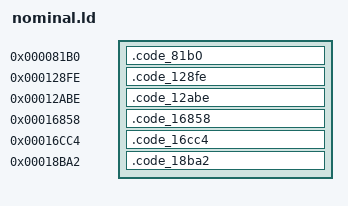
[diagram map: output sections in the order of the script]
OUTPUT_ARCH(riscv)
ENTRY(tsl9_queue_external_12abe)
PHDRS { code PT_LOAD FLAGS(5); }
SECTIONS {
  .code_81b0 0x81b0 : ALIGN(2) {
    KEEP(*(.text.tsl9_channel_external_81b0))
    KEEP(*(.text.tsl9_channel_clock_frame_81b6))
    KEEP(*(.text.tsl9_channel_clock_scale_81bc))
  } :code
  ASSERT(SIZEOF(.code_81b0) == 26, "Exact original extent")
  .code_128fe 0x128fe : ALIGN(2) {
    KEEP(*(.text.tsl9_channel_external_128fe))
    KEEP(*(.text.tsl9_filter_input_frame_12904))
    KEEP(*(.text.tsl9_filter_input_fill_1290a))
    KEEP(*(.text.tsl9_filter_input_cap_12920))
    KEEP(*(.text.tsl9_filter_input_small_1292c))
    KEEP(*(.text.tsl9_filter_input_copy_12930))
    KEEP(*(.text.tsl9_filter_input_loop_init_1293c))
    KEEP(*(.text.tsl9_filter_input_loop_12946))
    KEEP(*(.text.tsl9_filter_input_next_1298a))
    KEEP(*(.text.tsl9_filter_input_finish_1298e))
  } :code
  ASSERT(SIZEOF(.code_128fe) == 160, "Exact original extent")
  .code_12abe 0x12abe : ALIGN(2) {
    KEEP(*(.text.tsl9_queue_external_12abe))
    KEEP(*(.text.tsl9_channel_zero_12ac2))
    KEEP(*(.text.tsl9_channel_nonzero_12aca))
  } :code
  ASSERT(SIZEOF(.code_12abe) == 18, "Exact original extent")
  .code_16858 0x16858 : ALIGN(2) {
    KEEP(*(.text.tsl9_channel_external_16858))
    KEEP(*(.text.tsl9_channel_timer_args_1685a))
    KEEP(*(.text.tsl9_channel_timer_nonzero_16876))
    KEEP(*(.text.tsl9_channel_timer_zero_16888))
    KEEP(*(.text.tsl9_spi_transfer_entry_16896))
    KEEP(*(.text.tsl9_spi_tx_poll_1689e))
    KEEP(*(.text.tsl9_spi_tx_ready_168a6))
    KEEP(*(.text.tsl9_spi_rx_poll_168b6))
    KEEP(*(.text.tsl9_spi_rx_done_168be))
    KEEP(*(.text.tsl9_spi_tx_wait_168c8))
    KEEP(*(.text.tsl9_spi_timeout_168d0))
    KEEP(*(.text.tsl9_spi_rx_wait_168d4))
    KEEP(*(.text.tsl9_tagged_external_168de))
    KEEP(*(.text.tsl9_spi_write_guard1_168e6))
    KEEP(*(.text.tsl9_spi_write_select1_168f0))
    KEEP(*(.text.tsl9_spi_write_guard2_168fa))
    KEEP(*(.text.tsl9_spi_write_select2_168fe))
    KEEP(*(.text.tsl9_spi_write_command_16908))
    KEEP(*(.text.tsl9_spi_write_address_16910))
    KEEP(*(.text.tsl9_spi_write_test_1691a))
    KEEP(*(.text.tsl9_spi_write_finish_1691e))
    KEEP(*(.text.tsl9_spi_write_payload_16932))
    KEEP(*(.text.tsl9_tagged_external_1693e))
    KEEP(*(.text.tsl9_spi_modify_guard1_16942))
    KEEP(*(.text.tsl9_spi_modify_select1_16948))
    KEEP(*(.text.tsl9_spi_modify_guard2_16952))
    KEEP(*(.text.tsl9_spi_modify_select2_16956))
    KEEP(*(.text.tsl9_spi_modify_command_16960))
    KEEP(*(.text.tsl9_spi_modify_address_1696c))
    KEEP(*(.text.tsl9_spi_modify_mask_16974))
    KEEP(*(.text.tsl9_spi_modify_value_1697c))
    KEEP(*(.text.tsl9_spi_modify_finish_16984))
    KEEP(*(.text.tsl9_register_read_entry_16994))
    KEEP(*(.text.tsl9_register_read_body))
    KEEP(*(.text.tsl9_channel_external_169dc))
    KEEP(*(.text.tsl9_channel_mode_write_169e2))
    KEEP(*(.text.tsl9_channel_clock_start_169f8))
    KEEP(*(.text.tsl9_channel_poll_setup_169fc))
    KEEP(*(.text.tsl9_channel_poll_clock_16a00))
    KEEP(*(.text.tsl9_channel_timeout_16a0c))
    KEEP(*(.text.tsl9_channel_mode_return_16a0e))
    KEEP(*(.text.tsl9_channel_poll_read_16a1c))
    KEEP(*(.text.tsl9_channel_mode_done_16a2c))
    KEEP(*(.text.tsl9_register_write_entry_16a30))
    KEEP(*(.text.tsl9_register_write_body))
  } :code
  ASSERT(SIZEOF(.code_16858) == 548, "Exact original extent")
  .code_16cc4 0x16cc4 : ALIGN(2) {
    KEEP(*(.text.tsl9_channel_external_16cc4))
    KEEP(*(.text.tsl9_setup_resident_16cd2))
    KEEP(*(.text.tsl9_setup_frame_16cd8))
    KEEP(*(.text.tsl9_setup_clear_16ce6))
    KEEP(*(.text.tsl9_setup_length_16cfa))
    KEEP(*(.text.tsl9_setup_clamp_16d04))
    KEEP(*(.text.tsl9_setup_copy_16d06))
    KEEP(*(.text.tsl9_setup_mode_16d12))
    KEEP(*(.text.tsl9_setup_write0_16d1c))
    KEEP(*(.text.tsl9_setup_write1_16d2a))
    KEEP(*(.text.tsl9_setup_loop_init_16d3e))
    KEEP(*(.text.tsl9_setup_loop_16d4c))
    KEEP(*(.text.tsl9_setup_test_16d82))
    KEEP(*(.text.tsl9_setup_normal_16d86))
    KEEP(*(.text.tsl9_setup_final_16d8e))
    KEEP(*(.text.tsl9_setup_return_16d96))
    KEEP(*(.text.tsl9_setup_early_16daa))
  } :code
  ASSERT(SIZEOF(.code_16cc4) == 232, "Exact original extent")
  .code_18ba2 0x18ba2 : ALIGN(2) {
    KEEP(*(.text.tsl9_filter_program_18ba2))
    KEEP(*(.text.tsl9_filter_scale16_18bd4))
    KEEP(*(.text.tsl9_filter_fr2_18bfe))
    KEEP(*(.text.tsl9_filter_mode_18c04))
    KEEP(*(.text.tsl9_filter_mode_mask_18c12))
    KEEP(*(.text.tsl9_filter_mode_store_18c18))
    KEEP(*(.text.tsl9_filter_fifo_18c1c))
    KEEP(*(.text.tsl9_filter_fifo0_18c2a))
    KEEP(*(.text.tsl9_filter_activation_18c34))
    KEEP(*(.text.tsl9_filter_activate_18c3c))
    KEEP(*(.text.tsl9_filter_finish_18c4a))
    KEEP(*(.text.tsl9_filter_scale_test_18c5a))
    KEEP(*(.text.tsl9_filter_scale32_18c5e))
    KEEP(*(.text.tsl9_filter_mode_list_18c8a))
    KEEP(*(.text.tsl9_filter_fifo_test_18c92))
    KEEP(*(.text.tsl9_filter_fifo1_18c98))
  } :code
  ASSERT(SIZEOF(.code_18ba2) == 258, "Exact original extent")
  ASSERT(tsl9_channel_external_81b0 == 0x81b0, "Original FUNC address")
  ASSERT(tsl9_channel_clock_frame_81b6 == 0x81b6, "Original FUNC address")
  ASSERT(tsl9_channel_clock_scale_81bc == 0x81bc, "Original FUNC address")
  ASSERT(tsl9_channel_external_128fe == 0x128fe, "Original FUNC address")
  ASSERT(tsl9_filter_input_frame_12904 == 0x12904, "Original FUNC address")
  ASSERT(tsl9_filter_input_fill_1290a == 0x1290a, "Original FUNC address")
  ASSERT(tsl9_filter_input_cap_12920 == 0x12920, "Original FUNC address")
  ASSERT(tsl9_filter_input_small_1292c == 0x1292c, "Original FUNC address")
  ASSERT(tsl9_filter_input_copy_12930 == 0x12930, "Original FUNC address")
  ASSERT(tsl9_filter_input_loop_init_1293c == 0x1293c, "Original FUNC address")
  ASSERT(tsl9_filter_input_loop_12946 == 0x12946, "Original FUNC address")
  ASSERT(tsl9_filter_input_next_1298a == 0x1298a, "Original FUNC address")
  ASSERT(tsl9_filter_input_finish_1298e == 0x1298e, "Original FUNC address")
  ASSERT(tsl9_queue_external_12abe == 0x12abe, "Original FUNC address")
  ASSERT(tsl9_channel_zero_12ac2 == 0x12ac2, "Original FUNC address")
  ASSERT(tsl9_channel_nonzero_12aca == 0x12aca, "Original FUNC address")
  ASSERT(tsl9_channel_external_16858 == 0x16858, "Original FUNC address")
  ASSERT(tsl9_channel_timer_args_1685a == 0x1685a, "Original FUNC address")
  ASSERT(tsl9_channel_timer_nonzero_16876 == 0x16876, "Original FUNC address")
  ASSERT(tsl9_channel_timer_zero_16888 == 0x16888, "Original FUNC address")
  ASSERT(tsl9_spi_transfer_entry_16896 == 0x16896, "Original FUNC address")
  ASSERT(tsl9_spi_tx_poll_1689e == 0x1689e, "Original FUNC address")
  ASSERT(tsl9_spi_tx_ready_168a6 == 0x168a6, "Original FUNC address")
  ASSERT(tsl9_spi_rx_poll_168b6 == 0x168b6, "Original FUNC address")
  ASSERT(tsl9_spi_rx_done_168be == 0x168be, "Original FUNC address")
  ASSERT(tsl9_spi_tx_wait_168c8 == 0x168c8, "Original FUNC address")
  ASSERT(tsl9_spi_timeout_168d0 == 0x168d0, "Original FUNC address")
  ASSERT(tsl9_spi_rx_wait_168d4 == 0x168d4, "Original FUNC address")
  ASSERT(tsl9_tagged_external_168de == 0x168de, "Original FUNC address")
  ASSERT(tsl9_spi_write_guard1_168e6 == 0x168e6, "Original FUNC address")
  ASSERT(tsl9_spi_write_select1_168f0 == 0x168f0, "Original FUNC address")
  ASSERT(tsl9_spi_write_guard2_168fa == 0x168fa, "Original FUNC address")
  ASSERT(tsl9_spi_write_select2_168fe == 0x168fe, "Original FUNC address")
  ASSERT(tsl9_spi_write_command_16908 == 0x16908, "Original FUNC address")
  ASSERT(tsl9_spi_write_address_16910 == 0x16910, "Original FUNC address")
  ASSERT(tsl9_spi_write_test_1691a == 0x1691a, "Original FUNC address")
  ASSERT(tsl9_spi_write_finish_1691e == 0x1691e, "Original FUNC address")
  ASSERT(tsl9_spi_write_payload_16932 == 0x16932, "Original FUNC address")
  ASSERT(tsl9_tagged_external_1693e == 0x1693e, "Original FUNC address")
  ASSERT(tsl9_spi_modify_guard1_16942 == 0x16942, "Original FUNC address")
  ASSERT(tsl9_spi_modify_select1_16948 == 0x16948, "Original FUNC address")
  ASSERT(tsl9_spi_modify_guard2_16952 == 0x16952, "Original FUNC address")
  ASSERT(tsl9_spi_modify_select2_16956 == 0x16956, "Original FUNC address")
  ASSERT(tsl9_spi_modify_command_16960 == 0x16960, "Original FUNC address")
  ASSERT(tsl9_spi_modify_address_1696c == 0x1696c, "Original FUNC address")
  ASSERT(tsl9_spi_modify_mask_16974 == 0x16974, "Original FUNC address")
  ASSERT(tsl9_spi_modify_value_1697c == 0x1697c, "Original FUNC address")
  ASSERT(tsl9_spi_modify_finish_16984 == 0x16984, "Original FUNC address")
  ASSERT(tsl9_register_read_entry_16994 == 0x16994, "Original FUNC address")
  ASSERT(tsl9_register_read_body == 0x16998, "Original FUNC address")
  ASSERT(tsl9_channel_external_169dc == 0x169dc, "Original FUNC address")
  ASSERT(tsl9_channel_mode_write_169e2 == 0x169e2, "Original FUNC address")
  ASSERT(tsl9_channel_clock_start_169f8 == 0x169f8, "Original FUNC address")
  ASSERT(tsl9_channel_poll_setup_169fc == 0x169fc, "Original FUNC address")
  ASSERT(tsl9_channel_poll_clock_16a00 == 0x16a00, "Original FUNC address")
  ASSERT(tsl9_channel_timeout_16a0c == 0x16a0c, "Original FUNC address")
  ASSERT(tsl9_channel_mode_return_16a0e == 0x16a0e, "Original FUNC address")
  ASSERT(tsl9_channel_poll_read_16a1c == 0x16a1c, "Original FUNC address")
  ASSERT(tsl9_channel_mode_done_16a2c == 0x16a2c, "Original FUNC address")
  ASSERT(tsl9_register_write_entry_16a30 == 0x16a30, "Original FUNC address")
  ASSERT(tsl9_register_write_body == 0x16a34, "Original FUNC address")
  ASSERT(tsl9_channel_external_16cc4 == 0x16cc4, "Original FUNC address")
  ASSERT(tsl9_setup_resident_16cd2 == 0x16cd2, "Original FUNC address")
  ASSERT(tsl9_setup_frame_16cd8 == 0x16cd8, "Original FUNC address")
  ASSERT(tsl9_setup_clear_16ce6 == 0x16ce6, "Original FUNC address")
  ASSERT(tsl9_setup_length_16cfa == 0x16cfa, "Original FUNC address")
  ASSERT(tsl9_setup_clamp_16d04 == 0x16d04, "Original FUNC address")
  ASSERT(tsl9_setup_copy_16d06 == 0x16d06, "Original FUNC address")
  ASSERT(tsl9_setup_mode_16d12 == 0x16d12, "Original FUNC address")
  ASSERT(tsl9_setup_write0_16d1c == 0x16d1c, "Original FUNC address")
  ASSERT(tsl9_setup_write1_16d2a == 0x16d2a, "Original FUNC address")
  ASSERT(tsl9_setup_loop_init_16d3e == 0x16d3e, "Original FUNC address")
  ASSERT(tsl9_setup_loop_16d4c == 0x16d4c, "Original FUNC address")
  ASSERT(tsl9_setup_test_16d82 == 0x16d82, "Original FUNC address")
  ASSERT(tsl9_setup_normal_16d86 == 0x16d86, "Original FUNC address")
  ASSERT(tsl9_setup_final_16d8e == 0x16d8e, "Original FUNC address")
  ASSERT(tsl9_setup_return_16d96 == 0x16d96, "Original FUNC address")
  ASSERT(tsl9_setup_early_16daa == 0x16daa, "Original FUNC address")
  ASSERT(tsl9_filter_program_18ba2 == 0x18ba2, "Original FUNC address")
  ASSERT(tsl9_filter_scale16_18bd4 == 0x18bd4, "Original FUNC address")
  ASSERT(tsl9_filter_fr2_18bfe == 0x18bfe, "Original FUNC address")
  ASSERT(tsl9_filter_mode_18c04 == 0x18c04, "Original FUNC address")
  ASSERT(tsl9_filter_mode_mask_18c12 == 0x18c12, "Original FUNC address")
  ASSERT(tsl9_filter_mode_store_18c18 == 0x18c18, "Original FUNC address")
  ASSERT(tsl9_filter_fifo_18c1c == 0x18c1c, "Original FUNC address")
  ASSERT(tsl9_filter_fifo0_18c2a == 0x18c2a, "Original FUNC address")
  ASSERT(tsl9_filter_activation_18c34 == 0x18c34, "Original FUNC address")
  ASSERT(tsl9_filter_activate_18c3c == 0x18c3c, "Original FUNC address")
  ASSERT(tsl9_filter_finish_18c4a == 0x18c4a, "Original FUNC address")
  ASSERT(tsl9_filter_scale_test_18c5a == 0x18c5a, "Original FUNC address")
  ASSERT(tsl9_filter_scale32_18c5e == 0x18c5e, "Original FUNC address")
  ASSERT(tsl9_filter_mode_list_18c8a == 0x18c8a, "Original FUNC address")
  ASSERT(tsl9_filter_fifo_test_18c92 == 0x18c92, "Original FUNC address")
  ASSERT(tsl9_filter_fifo1_18c98 == 0x18c98, "Original FUNC address")
  /DISCARD/ : { *(.comment) *(.note*) *(.riscv.attributes) }
}
